# STM32MP13xx register map
File version: 1.5
CPU: CA7 r0p0, little endian, MPU, FPU, 4 interrupt priority bits
Registers are 32-bit, read-write, reset 0x0 unless marked. A register's access mark holds for its fields unless they carry their own. Offsets are from the block's base; [hi:lo] are bit positions; lines under a group give offsets from that group; {n}, {i} and the like mark numbered series; <NAME> marks a mode.

## DDRCTRL (part 3 of 3)
Base 0x5A003000
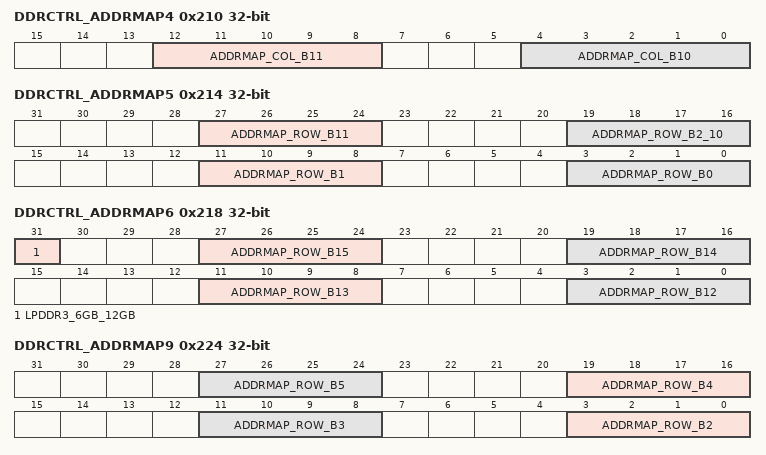
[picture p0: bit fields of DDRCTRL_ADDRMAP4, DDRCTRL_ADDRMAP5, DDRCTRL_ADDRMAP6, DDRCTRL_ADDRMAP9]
0x210 DDRCTRL_ADDRMAP4 — DDRCTRL address map register 4
  [12:8] ADDRMAP_COL_B11 — - Full bus width mode: Selects the HIF address bit used as column address bit 13 (11 in LPDDR2/LPDDR3 mode). - Half bus width mode: UNUSED. See later in this description for value you need to set to make it unused. - Quarter bus width mode: UNUSED. See later in this description for value you need to set to make it unused. Valid Range: 0 to 7, x, and 31. x indicate a valid value in inline ECC configuration. Internal Base: 11 The selected HIF address bit is determined by adding the internal base to the value of this field. Note: Per JEDEC DDR2/3/mDDR specification, column address bit 10 is reserved for indicating auto-precharge, and hence no source address bit can be mapped to column address bit 10. In LPDDR2/LPDDR3, there is a dedicated bit for auto-precharge in the CA bus and hence column bit 10 is used. In Inline ECC configuration (MEMC_INLINE_ECC=1) and ECC is enabled (ECCCFG0.ecc_mode>0), the highest 3 column address bits must map to the highest 3 valid HIF address bits. If column bit 11 is the highest column address bit, it must map to the highest valid HIF address bit. (x = the highest valid HIF address bit - internal base) If column bit 11 is the second highest column address bit, it must map to the second highest valid HIF address bit. (x = the highest valid HIF address bit - 1 - internal base) If column bit 11 is the third highest column address bit, it must map to the third highest valid HIF address bit. (x = the highest valid HIF address bit - 2 - internal base) If unused, set to 31 and then this column address bit is set to 0. Programming mode: Static
  [4:0] ADDRMAP_COL_B10 — - Full bus width mode: Selects the HIF address bit used as column address bit 11 (10 in LPDDR2/LPDDR3 mode). - Half bus width mode: Selects the HIF address bit used as column address bit 13 (11 in LPDDR2/LPDDR3 mode). - Quarter bus width mode: UNUSED. See later in this description for value you need to set to make it unused. Valid Range: 0 to 7, x, and 31. x indicate a valid value in inline ECC configuration. Internal Base: 10 The selected HIF address bit is determined by adding the internal base to the value of this field. Note: Per JEDEC DDR2/3/mDDR specification, column address bit 10 is reserved for indicating auto-precharge, and hence no source address bit can be mapped to column address bit 10. In LPDDR2/LPDDR3, there is a dedicated bit for auto-precharge in the CA bus and hence column bit 10 is used. In Inline ECC configuration (MEMC_INLINE_ECC=1) and ECC is enabled (ECCCFG0.ecc_mode>0), the highest 3 column address bits must map to the highest 3 valid HIF address bits. If column bit 10 is the highest column address bit, it must map to the highest valid HIF address bit. (x = the highest valid HIF address bit - internal base) If column bit 10 is the second highest column address bit, it must map to the second highest valid HIF address bit. (x = the highest valid HIF address bit - 1 - internal base) If column bit 10 is the third highest column address bit, it must map to the third highest valid HIF address bit. (x = the highest valid HIF address bit - 2 - internal base) If unused, set to 31 and then this column address bit is set to 0. Programming mode: Static
0x214 DDRCTRL_ADDRMAP5 — DDRCTRL address map register 5
  [27:24] ADDRMAP_ROW_B11 — Selects the HIF address bit used as row address bit 11. Valid Range: 0 to 11, and 15 Internal Base: 17 The selected HIF address bit is determined by adding the internal base to the value of this field. If unused, set to 15 and then row address bit 11 is set to 0. Programming mode: Static
  [19:16] ADDRMAP_ROW_B2_10 — Selects the HIF address bits used as row address bits 2 to 10. Valid Range: 0 to 11, and 15 Internal Base: 8 (for row address bit 2), 9 (for row address bit 3), 10 (for row address bit 4) etc increasing to 16 (for row address bit 10) The selected HIF address bit for each of the row address bits is determined by adding the internal base to the value of this field. When set to 15, the values of row address bits 2 to 10 are defined by registers ADDRMAP9, ADDRMAP10, ADDRMAP11. Programming mode: Static
  [11:8] ADDRMAP_ROW_B1 — Selects the HIF address bits used as row address bit 1. Valid Range: 0 to 11 Internal Base: 7 The selected HIF address bit for each of the row address bits is determined by adding the internal base to the value of this field. Programming mode: Static
  [3:0] ADDRMAP_ROW_B0 — Selects the HIF address bits used as row address bit 0. Valid Range: 0 to 11 Internal Base: 6 The selected HIF address bit for each of the row address bits is determined by adding the internal base to the value of this field. Programming mode: Static
0x218 DDRCTRL_ADDRMAP6 — DDRCTRL address register 6
  [31] LPDDR3_6GB_12GB — Set this to 1 if there is an LPDDR3 SDRAM 6Gb or 12Gb device in use. - 1 - LPDDR3 SDRAM 6Gb/12Gb device in use. Every address having row[14:13]==2'b11 is considered as invalid - 0 - non-LPDDR3 6Gb/12Gb device in use. All addresses are valid Present only in designs configured to support LPDDR3. Programming mode: Static
  [8n-93:8n-96] ADDRMAP_ROW_B{n} (n=12..15) — Selects the HIF address bit used as row address bit {n}. Valid Range: 0 to 11, and 15 Internal Base: {n+6} The selected HIF address bit is determined by adding the internal base to the value of this field. If unused, set to 15 and then row address bit {n} is set to 0. Programming mode: Static
0x224 DDRCTRL_ADDRMAP9 — DDRCTRL address map register 9
  [8n-13:8n-16] ADDRMAP_ROW_B{n} (n=2..5) — Selects the HIF address bits used as row address bit {n}. Valid Range: 0 to 11 Internal Base: {n+6} The selected HIF address bit for each of the row address bits is determined by adding the internal base to the value of this field. This register field is used only when ADDRMAP5.addrmap_row_b2_10 is set to value 15. Programming mode: Static
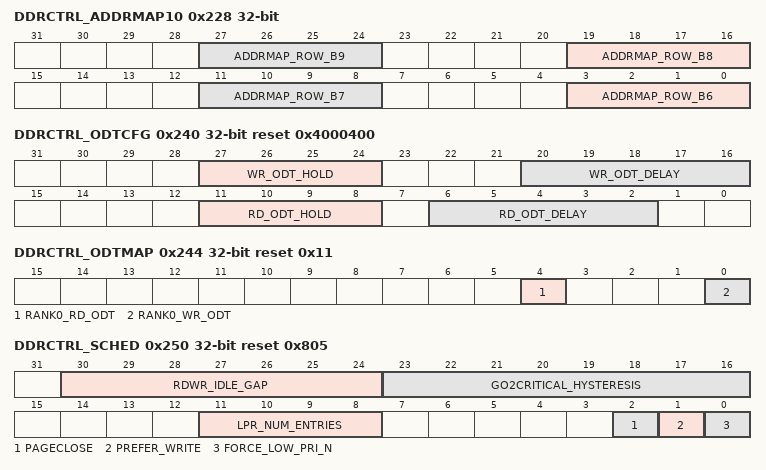
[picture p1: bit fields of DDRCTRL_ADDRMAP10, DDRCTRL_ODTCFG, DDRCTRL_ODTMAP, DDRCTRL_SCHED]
0x228 DDRCTRL_ADDRMAP10 — DDRCTRL address map register 10
  [8n-45:8n-48] ADDRMAP_ROW_B{n} (n=6..9) — Selects the HIF address bits used as row address bit {n}. Valid Range: 0 to 11 Internal Base: {n+6} The selected HIF address bit for each of the row address bits is determined by adding the internal base to the value of this field. This register field is used only when ADDRMAP5.addrmap_row_b2_10 is set to value 15. Programming mode: Static
0x22C DDRCTRL_ADDRMAP11 — DDRCTRL address map register 11
  [3:0] ADDRMAP_ROW_B10 — Selects the HIF address bits used as row address bit 10. Valid Range: 0 to 11 Internal Base: 16 The selected HIF address bit for each of the row address bits is determined by adding the internal base to the value of this field. This register field is used only when ADDRMAP5.addrmap_row_b2_10 is set to value 15. Programming mode: Static
0x240 DDRCTRL_ODTCFG reset 0x4000400 — DDRCTRL ODT configuration register
  [27:24] WR_ODT_HOLD — DFI PHY clock cycles to hold ODT for a write command. The minimum supported value is 2. Recommended values: DDR2: - BL8: 0x5 (DDR2-400/533/667), 0x6 (DDR2-800), 0x7 (DDR2-1066) - BL4: 0x3 (DDR2-400/533/667), 0x4 (DDR2-800), 0x5 (DDR2-1066) DDR3: - BL8: 0x6 DDR4: - BL8: 5 + WR_PREAMBLE + CRC_MODE WR_PREAMBLE = 1 (1tCK write preamble), 2 (2tCK write preamble) CRC_MODE = 0 (not CRC mode), 1 (CRC mode) LPDDR3: - BL8: 7 + RU(tODTon(max)/tCK) Programming mode: Quasi-dynamic Group 1 and Group 4
  [20:16] WR_ODT_DELAY — The delay, in DFI PHY clock cycles, from issuing a write command to setting ODT values associated with that command. ODT setting must remain constant for the entire time that DQS is driven by the DDRCTRL. Recommended values: DDR2: - CWL + AL - 3 (DDR2-400/533/667), CWL + AL - 4 (DDR2-800), CWL + AL - 5 (DDR2-1066) If (CWL + AL - 3 < 0), DDRCTRL does not support ODT for write operation. DDR3: - 0x0 DDR4: - DFITMG1.dfi_t_cmd_lat (to adjust for CAL mode) LPDDR3: - WL - 1 - RU(tODTon(max)/tCK)) Programming mode: Quasi-dynamic Group 1 and Group 4
  [11:8] RD_ODT_HOLD — DFI PHY clock cycles to hold ODT for a read command. The minimum supported value is 2. Recommended values: DDR2: - BL8: 0x6 (not DDR2-1066), 0x7 (DDR2-1066) - BL4: 0x4 (not DDR2-1066), 0x5 (DDR2-1066) DDR3: - BL8 - 0x6 DDR4: - BL8: 5 + RD_PREAMBLE RD_PREAMBLE = 1 (1tCK write preamble), 2 (2tCK write preamble) LPDDR3: - BL8: 5 + RU(tDQSCK(max)/tCK) - RD(tDQSCK(min)/tCK) + RU(tODTon(max)/tCK) Programming mode: Quasi-dynamic Group 1 and Group 4
  [6:2] RD_ODT_DELAY — The delay, in DFI PHY clock cycles, from issuing a read command to setting ODT values associated with that command. ODT setting must remain constant for the entire time that DQS is driven by the DDRCTRL. Recommended values: DDR2: - CL + AL - 4 (not DDR2-1066), CL + AL - 5 (DDR2-1066) If (CL + AL - 4 < 0), DDRCTRL does not support ODT for read operation. DDR3: - CL - CWL DDR4: - CL - CWL - RD_PREAMBLE + WR_PREAMBLE + DFITMG1.dfi_t_cmd_lat (to adjust for CAL mode) WR_PREAMBLE = 1 (1tCK write preamble), 2 (2tCK write preamble) RD_PREAMBLE = 1 (1tCK write preamble), 2 (2tCK write preamble) If (CL - CWL - RD_PREAMBLE + WR_PREAMBLE) < 0, DDRCTRL does not support ODT for read operation. LPDDR3: - RL + RD(tDQSCK(min)/tCK) - 1 - RU(tODTon(max)/tCK) Programming mode: Quasi-dynamic Group 1 and Group 4.
0x244 DDRCTRL_ODTMAP reset 0x11 — DDRCTRL ODT/Rank map register
  [4] RANK0_RD_ODT — Indicates which remote ODTs must be turned on during a read from rank 0. Each rank has a remote ODT (in the SDRAM) which can be turned on by setting the appropriate bit here. Rank 0 is controlled by the LSB; rank 1 is controlled by bit next to the LSB, etc. For each rank, set its bit to 1 to enable its ODT. Programming mode: Static
  [0] RANK0_WR_ODT — Indicates which remote ODTs must be turned on during a write to rank 0. Each rank has a remote ODT (in the SDRAM) which can be turned on by setting the appropriate bit here. Rank 0 is controlled by the LSB; rank 1 is controlled by bit next to the LSB, etc. For each rank, set its bit to 1 to enable its ODT. Programming mode: Static
0x250 DDRCTRL_SCHED reset 0x805 — DDRCTRL scheduler control register
  [30:24] RDWR_IDLE_GAP — When the preferred transaction store is empty for these many clock cycles, switch to the alternate transaction store if it is non-empty. The read transaction store (both high and low priority) is the default preferred transaction store and the write transaction store is the alternative store. When prefer write over read is set this is reversed. 0x0 is a legal value for this register. When set to 0x0, the transaction store switching happens immediately when the switching conditions become true. FOR PERFORMANCE ONLY Programming mode: Static
  [23:16] GO2CRITICAL_HYSTERESIS — UNUSED Programming mode: Static
  [11:8] LPR_NUM_ENTRIES — Number of entries in the low priority transaction store is this value + 1. (MEMC_NO_OF_ENTRY - (SCHED.lpr_num_entries + 1)) is the number of entries available for the high priority transaction store. Setting this to maximum value allocates all entries to low priority transaction store. Setting this to 0 allocates 1 entry to low priority transaction store and the rest to high priority transaction store. Note: In ECC configurations, the numbers of write and low priority read credits issued is one less than in the non-ECC case. One entry each is reserved in the write and low-priority read CAMs for storing the RMW requests arising out of single bit error correction RMW operation. Programming mode: Static
  [2] PAGECLOSE — If true, bank is kept open only while there are page hit transactions available in the CAM to that bank. The last read or write command in the CAM with a bank and page hit is executed with auto-precharge if SCHED1.pageclose_timer=0. Even if this register set to 1 and SCHED1.pageclose_timer is set to 0, explicit precharge (and not auto-precharge) may be issued in some cases where there is a mode switch between write and read or between LPR and HPR. The Read and Write commands that are executed as part of the ECC scrub requests are also executed without auto-precharge. If false, the bank remains open until there is a need to close it (to open a different page, or for page timeout or refresh timeout) - also known as open page policy. The open page policy can be overridden by setting the per-command-autopre bit on the HIF interface (hif_cmd_autopre). The pageclose feature provids a midway between Open and Close page policies. For performance only. Programming mode: Quasi-dynamic Group 3
  [1] PREFER_WRITE — If set then the bank selector prefers writes over reads. FOR DEBUG ONLY. Programming mode: Static
  [0] FORCE_LOW_PRI_N — Active low signal. When asserted ('0'), all incoming transactions are forced to low priority. This implies that all high priority read (HPR) and variable priority read commands (VPR) are treated as low priority read (LPR) commands. On the write side, all variable priority write (VPW) commands are treated as normal priority write (NPW) commands. Forcing the incoming transactions to low priority implicitly turns off bypass path for read commands. For performance only. Programming mode: Static
0x254 DDRCTRL_SCHED1 — DDRCTRL scheduler control register 1
  [7:0] PAGECLOSE_TIMER — This field works in conjunction with SCHED.pageclose. It only has meaning if SCHED.pageclose==1. If SCHED.pageclose==1 and pageclose_timer==0, then an auto-precharge may be scheduled for last read or write command in the CAM with a bank and page hit. Note, sometimes an explicit precharge is scheduled instead of the auto-precharge. See SCHED.pageclose for details of when this may happen. If SCHED.pageclose==1 and pageclose_timer>0, then an auto-precharge is not scheduled for last read or write command in the CAM with a bank and page hit. Instead, a timer is started, with pageclose_timer as the initial value. There is a timer on a per bank basis. The timer decrements unless the next read or write in the CAM to a bank is a page hit. It gets reset to pageclose_timer value if the next read or write in the CAM to a bank is a page hit. Once the timer has reached zero, an explicit precharge is attempted to be scheduled. Programming mode: Static.
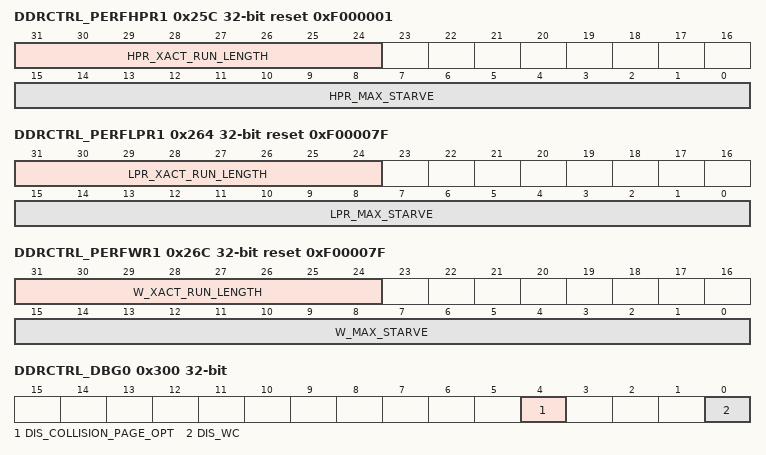
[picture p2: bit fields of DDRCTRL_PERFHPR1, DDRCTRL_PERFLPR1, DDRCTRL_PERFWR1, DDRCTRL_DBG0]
0x25C DDRCTRL_PERFHPR1 reset 0xF000001 — DDRCTRL high priority read CAM register 1
  [31:24] HPR_XACT_RUN_LENGTH — Number of transactions that are serviced once the HPR queue goes critical is the smaller of: - (a) This number - (b) Number of transactions available. Unit: Transaction. For performance only. Programming mode: Quasi-dynamic Group 3
  [15:0] HPR_MAX_STARVE — Number of DFI clocks that the HPR queue can be starved before it goes critical. The minimum valid functional value for this register is 0x1. Programming it to 0x0 disables the starvation functionality; during normal operation, this function must not be disabled as it causes excessive latencies. For performance only. Programming mode: Quasi-dynamic Group 3
0x264 DDRCTRL_PERFLPR1 reset 0xF00007F — DDRCTRL low priority read CAM register 1
  [31:24] LPR_XACT_RUN_LENGTH — Number of transactions that are serviced once the LPR queue goes critical is the smaller of: - (a) This number - (b) Number of transactions available. Unit: Transaction. For performance only Programming mode: Quasi-dynamic group 3
  [15:0] LPR_MAX_STARVE — Number of DFI clocks that the LPR queue can be starved before it goes critical. The minimum valid functional value for this register is 0x1. Programming it to 0x0 disables the starvation functionality; during normal operation, this function must be disabled as it causes excessive latencies. For performance only Programming mode: Quasi-dynamic Group 3
0x26C DDRCTRL_PERFWR1 reset 0xF00007F — DDRCTRL write CAM register 1
  [31:24] W_XACT_RUN_LENGTH — Number of transactions that are serviced once the WR queue goes critical is the smaller of: - (a) This number - (b) Number of transactions available. Unit: Transaction. For performance only. Programming mode: Quasi-dynamic Group 3.
  [15:0] W_MAX_STARVE — Number of DFI clocks that the WR queue can be starved before it goes critical. The minimum valid functional value for this register is 0x1. Programming it to 0x0 disables the starvation functionality; during normal operation, this function must not be disabled as it causes excessive latencies. For performance only. Programming mode: Quasi-dynamic Group 3.
0x300 DDRCTRL_DBG0 — DDRCTRL debug register 0
  [4] DIS_COLLISION_PAGE_OPT — When this is set to '0', auto-precharge is disabled for the flushed command in a collision case. Collision cases are write followed by read to same address, read followed by write to same address, or write followed by write to same address with DBG0.dis_wc bit = 1 (where same address comparisons exclude the two address bits representing critical word). FOR DEBUG ONLY. Programming mode: Static
  [0] DIS_WC — When 1, disable write combine. FOR DEBUG ONLY Programming mode: Static
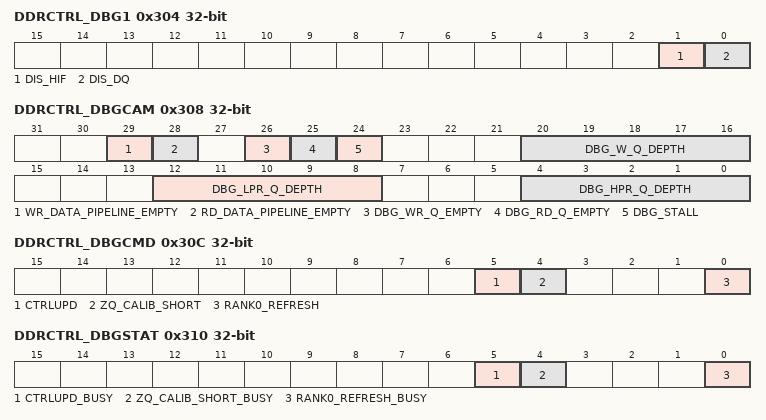
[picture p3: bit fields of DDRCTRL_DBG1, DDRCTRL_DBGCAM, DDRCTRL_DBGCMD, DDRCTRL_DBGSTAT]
0x304 DDRCTRL_DBG1 — DDRCTRL debug register 1
  [1] DIS_HIF — When 1, DDRCTRL asserts the HIF command signal hif_cmd_stall. DDRCTRL ignores the hif_cmd_valid and all other associated request signals. This bit is intended to be switched on-the-fly. Programming mode: Dynamic
  [0] DIS_DQ — When 1, DDRCTRL does not de-queue any transactions from the CAM. Bypass is also disabled. All transactions are queued in the CAM. No reads or writes are issued to SDRAM as long as this is asserted. This bit may be used to prevent reads or writes being issued by the DDRCTRL, which makes it safe to modify certain register fields associated with reads and writes (see User Guide for details). After setting this bit, it is strongly recommended to poll DBGCAM.wr_data_pipeline_empty and DBGCAM.rd_data_pipeline_empty, before making changes to any registers which affect reads and writes. This ensures that the relevant logic in the DDRC is idle. This bit is intended to be switched on-the-fly. Programming mode: Dynamic
0x308 DDRCTRL_DBGCAM ro — DDRCTRL CAM debug register
  [29] WR_DATA_PIPELINE_EMPTY — This bit indicates that the write data pipeline on the DFI interface is empty. This register is intended to be polled at least twice after setting DBG1.dis_dq, to ensure that all remaining commands/data have completed. Programming mode: Dynamic.
  [28] RD_DATA_PIPELINE_EMPTY — This bit indicates that the read data pipeline on the DFI interface is empty. This register is intended to be polled at least twice after setting DBG1.dis_dq, to ensure that all remaining commands/data have completed. Programming mode: Dynamic.
  [26] DBG_WR_Q_EMPTY — When 1, all the Write command queues and Write data buffers inside DDRC are empty. This register is to be used for debug purpose. An example use-case scenario: When Controller enters Self-Refresh using the Low-Power entry sequence, Controller is expected to have executed all the commands in its queues and the write and read data drained. Hence this register should be 1 at that time. For debug only. Programming mode: Dynamic.
  [25] DBG_RD_Q_EMPTY — When 1, all the Read command queues and Read data buffers inside DDRC are empty. This register is to be used for debug purpose. An example use-case scenario: When Controller enters Self-Refresh using the Low-Power entry sequence, Controller is expected to have executed all the commands in its queues and the write and read data drained. Hence this register should be 1 at that time. For debug only. Programming mode: Dynamic
  [24] DBG_STALL — Stall For debug only. Programming mode: Dynamic
  [20:16] DBG_W_Q_DEPTH — Write queue depth The last entry of WR queue is reserved for ECC SCRUB operation. This entry is not included in the calculation of the queue depth. For debug only. Programming mode: Dynamic
  [12:8] DBG_LPR_Q_DEPTH — Low priority read queue depth The last entry of Lpr queue is reserved for ECC SCRUB operation. This entry is not included in the calculation of the queue depth. For debug only. Programming mode: Dynamic
  [4:0] DBG_HPR_Q_DEPTH — High priority read queue depth For debug only. Programming mode: Dynamic
0x30C DDRCTRL_DBGCMD — DDRCTRL command debug register
  [5] CTRLUPD — Setting this register bit to 1 indicates to the DDRCTRL to issue a dfi_ctrlupd_req to the PHY. When this request is stored in the DDRCTRL, the bit is automatically cleared. This operation must only be performed when DFIUPD0.dis_auto_ctrlupd=1. Programming mode: Dynamic.
  [4] ZQ_CALIB_SHORT — Setting this register bit to 1 indicates to the DDRCTRL to issue a ZQCS (ZQ calibration short)/MPC(ZQ calibration) command to the SDRAM. When this request is stored in the DDRCTRL, the bit is automatically cleared. This operation can be performed only when ZQCTL0.dis_auto_zq=1. It is recommended NOT to set this register bit if in Init, in Self-Refresh(except LPDDR4) or SR-Powerdown(LPDDR4) or Deep power-down operating modes or maximum power saving mode. For self-refresh(except LPDDR4) or SR-powerdown(LPDDR4) it is scheduled after SR(except LPDDR4) or SPRD(LPDDR4) has been exited. For Deep power down and maximum power saving mode, it is not scheduled, although DBGSTAT.zq_calib_short_busy is de-asserted. Programming mode: Dynamic.
  [0] RANK0_REFRESH — Setting this register bit to 1 indicates to the DDRCTRL to issue a refresh to rank 0. Writing to this bit causes DBGSTAT.rank0_refresh_busy to be set. When DBGSTAT.rank0_refresh_busy is cleared, the command has been stored in DDRCTRL. For 3DS configuration, refresh is sent to rank index 0. This operation can be performed only when RFSHCTL3.dis_auto_refresh=1. It is recommended NOT to set this register bit if in Init or Deep power-down operating modes or Maximum Power Saving Mode. Programming mode: Dynamic.
0x310 DDRCTRL_DBGSTAT ro — DDRCTRL status debug register
  [5] CTRLUPD_BUSY — SoC core may initiate a ctrlupd operation only if this signal is low. This signal goes high in the clock after the DDRCTRL accepts the ctrlupd request. It goes low when the ctrlupd operation is initiated in the DDRCTRL. It is recommended not to perform ctrlupd operations when this signal is high. - 0 - Indicates that the SoC core can initiate a ctrlupd operation - 1 - Indicates that ctrlupd operation has not been initiated yet in the DDRCTRL Programming mode: Dynamic
  [4] ZQ_CALIB_SHORT_BUSY — SoC core may initiate a ZQCS (ZQ calibration short) operation only if this signal is low. This signal goes high in the clock after the DDRCTRL accepts the ZQCS request. It goes low when the ZQCS operation is initiated in the DDRCTRL. It is recommended not to perform ZQCS operations when this signal is high. - 0 - Indicates that the SoC core can initiate a ZQCS operation - 1 - Indicates that ZQCS operation has not been initiated yet in the DDRCTRL Programming mode: Dynamic
  [0] RANK0_REFRESH_BUSY — SoC core may initiate a rank0_refresh operation (refresh operation to rank 0) only if this signal is low. This signal goes high in the clock after DBGCMD.rank0_refresh is set to one. It goes low when the rank0_refresh operation is stored in the DDRCTRL. It is recommended not to perform rank0_refresh operations when this signal is high. - 0 - Indicates that the SoC core can initiate a rank0_refresh operation - 1 - Indicates that rank0_refresh operation has not been stored yet in the DDRCTRL Programming mode: Dynamic
0x320 DDRCTRL_SWCTL reset 0x1 — DDRCTRL software register programming control enable
  [0] SW_DONE — Enable quasi-dynamic register programming outside reset. Program register to 0 to enable quasi-dynamic programming. Set back register to 1 once programming is done. Programming mode: Dynamic
0x324 DDRCTRL_SWSTAT ro reset 0x1 — DDRCTRL software register programming control status
  [0] SW_DONE_ACK — Register programming done. This register is the echo of SWCTL.sw_done. Wait for sw_done value 1 to propagate to sw_done_ack at the end of the programming sequence to ensure that the correct registers values are propagated to the destination clock domains. Programming mode: Static
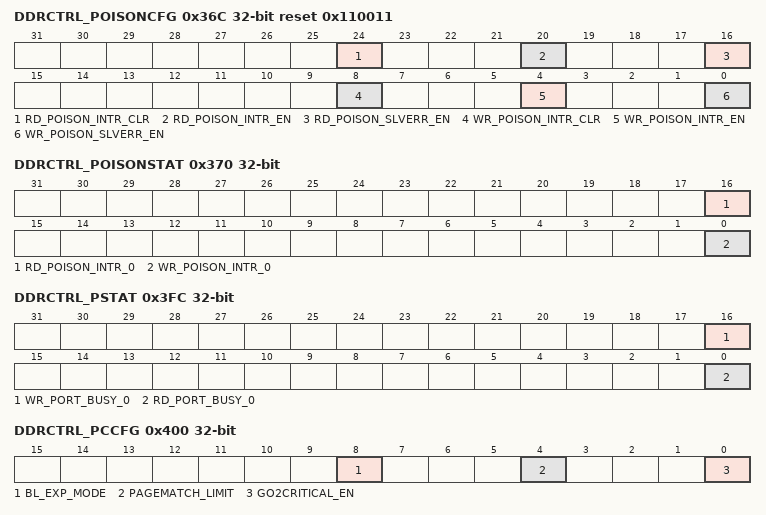
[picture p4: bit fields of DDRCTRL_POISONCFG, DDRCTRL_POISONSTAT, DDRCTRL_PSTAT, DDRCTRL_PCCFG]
0x36C DDRCTRL_POISONCFG reset 0x110011 — DDRCTRL AXI Poison configuration register
  [24] RD_POISON_INTR_CLR — Interrupt clear for read transaction poisoning. Allow 2/3 clock cycles for correct value to propagate to core logic and clear the interrupts. Programming mode: Dynamic
  [20] RD_POISON_INTR_EN — If set to 1, enables interrupts for read transaction poisoning Programming mode: Dynamic
  [16] RD_POISON_SLVERR_EN — If set to 1, enables SLVERR response for read transaction poisoning Programming mode: Dynamic
  [8] WR_POISON_INTR_CLR — Interrupt clear for write transaction poisoning. Allow 2/3 clock cycles for correct value to propagate to core logic and clear the interrupts. Programming mode: Dynamic
  [4] WR_POISON_INTR_EN — If set to 1, enables interrupts for write transaction poisoning Programming mode: Dynamic
  [0] WR_POISON_SLVERR_EN — If set to 1, enables SLVERR response for write transaction poisoning Programming mode: Dynamic
0x370 DDRCTRL_POISONSTAT ro — DDRCTRL AXI Poison status register
  [16] RD_POISON_INTR_0 — Read transaction poisoning error interrupt for port 0. This register is a APB clock copy (double register synchronizer) of the interrupt asserted when a transaction is poisoned on the corresponding AXI port's read address channel. Bit 0 corresponds to Port 0, and so on. Interrupt is cleared by register rd_poison_intr_clr, then value propagated to APB clock. Programming mode: Dynamic
  [0] WR_POISON_INTR_0 — Write transaction poisoning error interrupt for port 0. This register is a APB clock copy (double register synchronizer) of the interrupt asserted when a transaction is poisoned on the corresponding AXI port's write address channel. Bit 0 corresponds to Port 0, and so on. Interrupt is cleared by register wr_poison_intr_clr, then value propagated to APB clock. Programming mode: Dynamic
0x3FC DDRCTRL_PSTAT ro — DDRCTRL port status register
  [16] WR_PORT_BUSY_0 — Indicates if there are outstanding writes for AXI port 0. Programming mode: Dynamic
  [0] RD_PORT_BUSY_0 — Indicates if there are outstanding reads for AXI port 0. Programming mode: Dynamic
0x400 DDRCTRL_PCCFG — DDRCTRL port common configuration register
  [8] BL_EXP_MODE — Burst length expansion mode. By default (i.e. bl_exp_mode==0) XPI expands every AXI burst into multiple HIF commands, using the memory burst length as a unit. If set to 1, then XPI uses half of the memory burst length as a unit. This applies to both reads and writes. When MSTR.data_bus_width==00, setting bl_exp_mode to 1 has no effect. This can be used in cases where Partial Writes is enabled (UMCTL2_PARTIAL_WR=1), in order to avoid or minimize t_ccd_l penalty in DDR4 and t_ccd_mw penalty in LPDDR4. Hence, bl_exp_mode=1 is only recommended if DDR4 or LPDDR4. Note that if DBICTL.dm_en=0, functionality is not supported in the following cases: - UMCTL2_PARTIAL_WR=0 - UMCTL2_PARTIAL_WR=1, MSTR.data_bus_width=01, MEMC_BURST_LENGTH=8 and MSTR.burst_rdwr=1000 (LPDDR4 only) - UMCTL2_PARTIAL_WR=1, MSTR.data_bus_width=01, MEMC_BURST_LENGTH=4 and MSTR.burst_rdwr=0100 (DDR4 only), with either MSTR.burstchop=0 or CRCPARCTL1.crc_enable=1 Functionality is also not supported if Data Channel Interleave is enabled. Programming mode: Static.
  [4] PAGEMATCH_LIMIT — Page match four limit. If set to 1, limits the number of consecutive same page DDRC transactions that can be granted by the Port Arbiter to four when Page Match feature is enabled. If set to 0, there is no limit imposed on number of consecutive same page DDRC transactions. Programming mode: Static.
  [0] GO2CRITICAL_EN — If set to 1 (enabled), sets co_gs_go2critical_wr and co_gs_go2critical_lpr/co_gs_go2critical_hpr signals going to DDRC based on urgent input (awurgent, arurgent) coming from AXI master. If set to 0 (disabled), co_gs_go2critical_wr and co_gs_go2critical_lpr/co_gs_go2critical_hpr signals at DDRC are driven to 1b'0. Programming mode: Static.
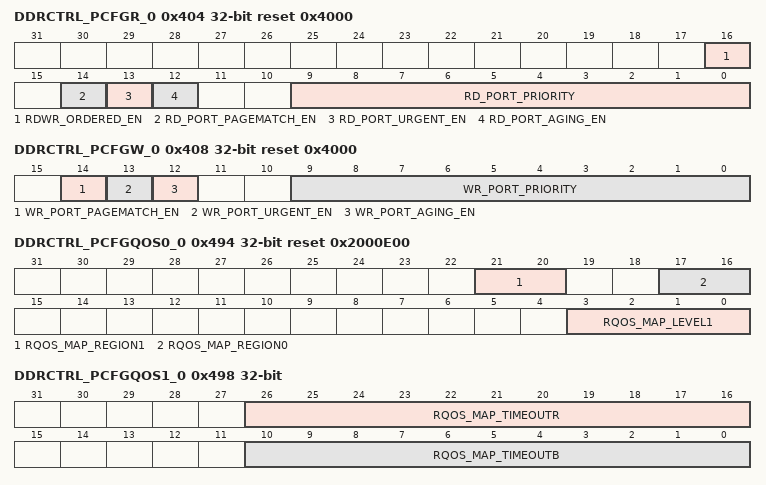
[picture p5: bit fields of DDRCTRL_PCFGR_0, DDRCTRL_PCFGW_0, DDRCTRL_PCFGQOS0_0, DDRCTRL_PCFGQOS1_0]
0x404 DDRCTRL_PCFGR_0 reset 0x4000 — DDRCTRL port x configuration read register
  [16] RDWR_ORDERED_EN — Enables ordered read/writes. If set to 1, preserves the ordering between read transaction and write transaction issued to the same address, on a given port. In other words, the controller ensures that all same address read and write commands from the application port interface are transported to the DFI interface in the order of acceptance. This feature is useful in cases where software coherency is desired for masters issuing back-to-back read/write transactions without waiting for write/read responses. Note that this register has an effect only if necessary logic is instantiated via the UMCTL2_RDWR_ORDERED_n parameter. Programming mode: Static.
  [14] RD_PORT_PAGEMATCH_EN — If set to 1, enables the Page Match feature. If enabled, once a requesting port is granted, the port is continued to be granted if the following immediate commands are to the same memory page (same bank and same row). See also related PCCFG.pagematch_limit register. Programming mode: Static
  [13] RD_PORT_URGENT_EN — If set to 1, enables the AXI urgent sideband signal (arurgent). When enabled and arurgent is asserted by the master, that port becomes the highest priority and co_gs_go2critical_lpr/co_gs_go2critical_hpr signal to DDRC is asserted if enabled in PCCFG.go2critical_en register. Note that arurgent signal can be asserted anytime and as long as required which is independent of address handshaking (it is not associated with any particular command). Programming mode: Static
  [12] RD_PORT_AGING_EN — If set to 1, enables aging function for the read channel of the port. Programming mode: Static
  [9:0] RD_PORT_PRIORITY — Determines the initial load value of read aging counters. These counters are parallel loaded after reset, or after each grant to the corresponding port. The aging counters down-count every clock cycle where the port is requesting but not granted. The higher significant 5-bits of the read aging counter sets the priority of the read channel of a given port. Port's priority increases as the higher significant 5-bits of the counter starts to decrease. When the aging counter becomes 0, the corresponding port channel has the highest priority level (timeout condition - Priority0). For multi-port configurations, the aging counters cannot be used to set port priorities when external dynamic priority inputs (arqos) are enabled (timeout is still applicable). For single port configurations, the aging counters are only used when they timeout (become 0) to force read-write direction switching. In this case, external dynamic priority input, arqos (for reads only) can still be used to set the DDRC read priority (2 priority levels: low priority read - LPR, high priority read - HPR) on a command by command basis. Note: The two LSBs of this register field are tied internally to 2'b00. Programming mode: Static
0x408 DDRCTRL_PCFGW_0 reset 0x4000 — DDRCTRL port x configuration write register
  [14] WR_PORT_PAGEMATCH_EN — If set to 1, enables the Page Match feature. If enabled, once a requesting port is granted, the port is continued to be granted if the following immediate commands are to the same memory page (same bank and same row). See also related PCCFG.pagematch_limit register. Programming mode: Static
  [13] WR_PORT_URGENT_EN — If set to 1, enables the AXI urgent sideband signal (awurgent). When enabled and awurgent is asserted by the master, that port becomes the highest priority and co_gs_go2critical_wr signal to DDRC is asserted if enabled in PCCFG.go2critical_en register. Note that awurgent signal can be asserted anytime and as long as required which is independent of address handshaking (it is not associated with any particular command). Programming mode: Static
  [12] WR_PORT_AGING_EN — If set to 1, enables aging function for the write channel of the port. Programming mode: Static
  [9:0] WR_PORT_PRIORITY — Determines the initial load value of write aging counters. These counters are parallel loaded after reset, or after each grant to the corresponding port. The aging counters down-count every clock cycle where the port is requesting but not granted. The higher significant 5-bits of the write aging counter sets the initial priority of the write channel of a given port. Port's priority increases as the higher significant 5-bits of the counter starts to decrease. When the aging counter becomes 0, the corresponding port channel has the highest priority level. For multi-port configurations, the aging counters cannot be used to set port priorities when external dynamic priority inputs (awqos) are enabled (timeout is still applicable). For single port configurations, the aging counters are only used when they timeout (become 0) to force read-write direction switching. Note: The two LSBs of this register field are tied internally to 2'b00. Programming mode: Static
0x490 DDRCTRL_PCTRL_0 — DDRCTRL port x control register
  [0] PORT_EN — Enables AXI port n. Programming mode: Dynamic
0x494 DDRCTRL_PCFGQOS0_0 reset 0x2000E00 — DDRCTRL port x read Q0S configuration register 0
  [21:20] RQOS_MAP_REGION1 — This bitfield indicates the traffic class of region 1. Valid values are: -0: LPR, -1: VPR, - 2: HPR. For dual address queue configurations, region1 maps to the blue address queue. In this case, valid values are -0: LPR and -1: VPR only. When VPR support is disabled (UMCTL2_VPR_EN = 0) and traffic class of region 1 is set to 1 (VPR), VPR traffic is aliased to LPR traffic. Programming mode: Quasi-dynamic Group 3
  [17:16] RQOS_MAP_REGION0 — This bitfield indicates the traffic class of region 0. Valid values are: -0: LPR, 1: VPR, 2: HPR. For dual address queue configurations, region 0 maps to the blue address queue. In this case, valid values are: -0: LPR and 1: VPR only. When VPR support is disabled (UMCTL2_VPR_EN = 0) and traffic class of region0 is set to 1 (VPR), VPR traffic is aliased to LPR traffic. Programming mode: Quasi-dynamic Group 3
  [3:0] RQOS_MAP_LEVEL1 — Separation level1 indicating the end of region0 mapping; start of region0 is 0. Possible values for level1 are 0 to 13 (for dual RAQ) or 0 to 14 (for single RAQ) which corresponds to arqos. Note that for PA, arqos values are used directly as port priorities, where the higher the value corresponds to higher port priority. All of the map_level* registers must be set to distinct values. Programming mode: Quasi-dynamic Group 3
0x498 DDRCTRL_PCFGQOS1_0 — DDRCTRL port x read Q0S configuration register 1
  [26:16] RQOS_MAP_TIMEOUTR — Specifies the timeout value for transactions mapped to the red address queue. With single read address queue, there is no red queue and this value has no effect. Programming mode: Quasi-dynamic Group 3
  [10:0] RQOS_MAP_TIMEOUTB — Specifies the timeout value for transactions mapped to the blue address queue. Programming mode: Quasi-dynamic Group 3.
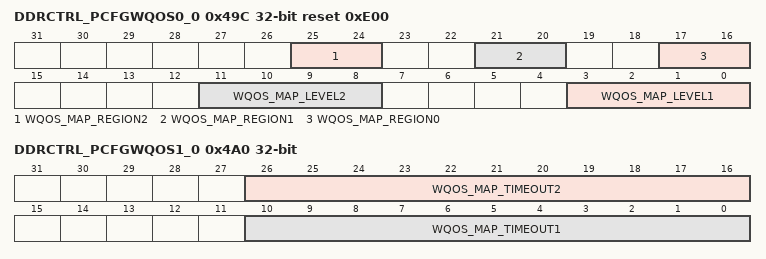
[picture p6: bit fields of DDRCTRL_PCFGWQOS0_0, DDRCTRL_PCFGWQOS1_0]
0x49C DDRCTRL_PCFGWQOS0_0 reset 0xE00 — DDRCTRL port x write Q0S configuration register 0
  [25:24] WQOS_MAP_REGION2 — This bitfield indicates the traffic class of region 2. Valid values are: When VPW support is disabled (UMCTL2_VPW_EN = 0) and traffic class of region 2 is set to 1 (VPW), VPW traffic is aliased to NPW traffic. Programming mode: Quasi-dynamic Group 3
    0=NPW, 1: VPW
  [21:20] WQOS_MAP_REGION1 — This bitfield indicates the traffic class of region 1. Valid values are: When VPW support is disabled (UMCTL2_VPW_EN = 0) and traffic class of region 1 is set to 1 (VPW), VPW traffic is aliased to NPW traffic. Programming mode: Quasi-dynamic Group 3
    0=NPW, 1: VPW
  [17:16] WQOS_MAP_REGION0 — This bitfield indicates the traffic class of region 0. Valid values are: When VPW support is disabled (UMCTL2_VPW_EN = 0) and traffic class of region 0 is set to 1 (VPW), VPW traffic is aliased to NPW traffic. Programming mode: Quasi-dynamic Group 3
    0=NPW, 1: VPW
  [11:8] WQOS_MAP_LEVEL2 — Separation level2 indicating the end of region1 mapping; start of region1 is (level1 + 1). Possible values for level2 are (level1 + 1) to 14 which corresponds to awqos. Region2 starts from (level2 + 1) up to 15. Note that for PA, awqos values are used directly as port priorities, where the higher the value corresponds to higher port priority. All of the map_level* registers must be set to distinct values. Programming mode: Quasi-dynamic Group 3
  [3:0] WQOS_MAP_LEVEL1 — Separation level indicating the end of region0 mapping; start of region0 is 0. Possible values for level1 are 0 to 13 which corresponds to awqos. Note that for PA, awqos values are used directly as port priorities, where the higher the value corresponds to higher port priority. All of the map_level* registers must be set to distinct values. Programming mode: Quasi-dynamic Group 3
0x4A0 DDRCTRL_PCFGWQOS1_0 — DDRCTRL port x write Q0S configuration register 1
  [26:16] WQOS_MAP_TIMEOUT2 — Specifies the timeout value for write transactions in region 2. Programming mode: Quasi-dynamic Group 3.
  [10:0] WQOS_MAP_TIMEOUT1 — Specifies the timeout value for write transactions in region 0 and 1. Programming mode: Quasi-dynamic Group 3.
